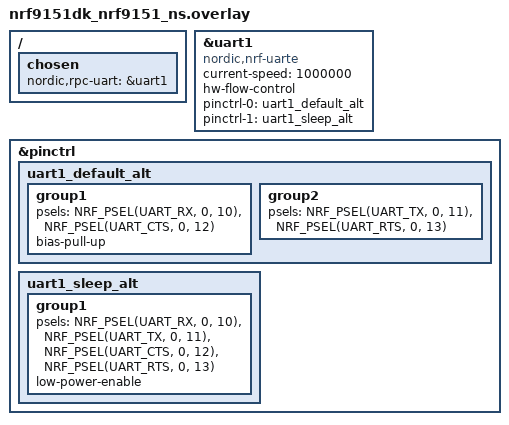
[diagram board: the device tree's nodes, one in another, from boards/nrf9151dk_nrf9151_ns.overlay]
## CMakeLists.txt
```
# Copyright (c) 2026 Nordic Semiconductor ASA
# SPDX-License-Identifier: LicenseRef-Nordic-5-Clause

cmake_minimum_required(VERSION 3.20.0)
find_package(Zephyr REQUIRED HINTS $ENV{ZEPHYR_BASE})
project(dect_rpc_server)

target_sources(app PRIVATE src/main.c)
```

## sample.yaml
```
# Copyright (c) 2026 Nordic Semiconductor ASA
# SPDX-License-Identifier: LicenseRef-Nordic-5-Clause

sample:
  name: DECT NR+ RPC server

common:
  tags:
    - ci_build
    - sysbuild
    - ci_samples_dect
  sysbuild: true
  build_only: true
  integration_platforms:
    - nrf9151dk/nrf9151/ns
  platform_allow:
    - nrf9151dk/nrf9151/ns

tests:
  sample.dect.dect_rpc_server: {}
  sample.dect.dect_rpc_server.rpc_uart_reliable:
    extra_args: EXTRA_CONF_FILE=rpc-uart-reliable.conf
```

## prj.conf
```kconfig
CONFIG_DECT=y

# Usually these RPC server is used when acting as PT
CONFIG_DECT_DEFAULT_DEV_TYPE_PT=y

# Modem library
CONFIG_NRF_MODEM_LIB=y
CONFIG_NRF_MODEM_LINK_BINARY_DECT=y
CONFIG_NRF_MODEM_LIB_ON_FAULT_APPLICATION_SPECIFIC=y
CONFIG_NRF_MODEM_LIB_SHMEM_RX_SIZE=6144
CONFIG_NRF_MODEM_LIB_SHMEM_TX_SIZE=12288
CONFIG_NRF_MODEM_LIB_CFUN_HOOKS=n
CONFIG_NRF_MODEM_LIB_TRACE=n

# DECT NR+ core and RPC sample
CONFIG_DECT_NR_RPC=y
CONFIG_DECT_NR_RPC_SERVER=y
CONFIG_DECT_NR_RPC_NET_IF=y
CONFIG_DECT_NR_RPC_SHELL=y

# DECT NR+ driver configuration
CONFIG_DECT_MDM=y
CONFIG_DECT_MDM_DRIVER_NRF=y

CONFIG_DECT_CLUSTER_MAX_CHILD_ASSOCIATION_COUNT=10
CONFIG_NET_IPV6_MAX_NEIGHBORS=10

CONFIG_DECT_MDM_NET_IF_NO_AUTO_START=n
CONFIG_NET_L2_DECT=y
CONFIG_NET_L2_DECT_MGMT=y

# Settings storage (DECT_MDM depends on SETTINGS; NVS backend needs FLASH + NVS)
CONFIG_FLASH=y
CONFIG_FLASH_MAP=y
CONFIG_MPU_ALLOW_FLASH_WRITE=y
CONFIG_NVS=y
CONFIG_SETTINGS=y
CONFIG_SETTINGS_NVS=y

# Modem configuration (align with dect_shell: MODEM_INFO for FW version in dect status)
CONFIG_MODEM_ANTENNA=n
CONFIG_MODEM_INFO=y
CONFIG_MODEM_INFO_ADD_NETWORK=n
CONFIG_MODEM_INFO_ADD_SIM=n

# nRF RPC over UART (server is initiator; init in main() after modem, no shell command)
CONFIG_NRF_RPC_UART_TRANSPORT=y
CONFIG_DECT_NR_RPC_UART_TRANSPORT=y
CONFIG_NRF_RPC_UART_RX_RINGBUF_SIZE=8192
CONFIG_NRF_RPC_GROUP_DEFAULT_INITIATOR=y
CONFIG_NRF_RPC_GROUP_INIT_WAIT_TIME=15000

# Default: non-reliable UART RPC (for throughput). Add rpc-uart-reliable.conf for reliable mode.
CONFIG_NRF_RPC_UART_RELIABLE=n
CONFIG_NRF_RPC_RESPONSE_TIMEOUT=50
CONFIG_NRF_RPC_CBOR=y
CONFIG_NRF_RPC_ZCBOR_BACKUPS=1
CONFIG_NRF_RPC_THREAD_STACK_SIZE=5632

CONFIG_NRF_RPC_THREAD_PRIORITY=0
CONFIG_NRF_RPC_THREAD_POOL_SIZE=5
CONFIG_NRF_RPC_CMD_CTX_POOL_SIZE=12

# DECT NR+ RPC server event pacing
CONFIG_DECT_NR_RPC_SERVER_EVT_PACING_MS=0

# UART
CONFIG_UART_LINE_CTRL=y
CONFIG_UART_INTERRUPT_DRIVEN=y

# Networking
CONFIG_NETWORKING=y
CONFIG_NET_NATIVE=y
CONFIG_NET_IPV6=y
CONFIG_NET_IPV4=n
CONFIG_NET_SOCKETS=y
CONFIG_NET_SOCKETS_OFFLOAD=n
CONFIG_NET_MGMT=y
CONFIG_NET_MGMT_EVENT=y
CONFIG_NET_MGMT_EVENT_INFO=y
CONFIG_NET_MGMT_EVENT_INFO_DEFAULT_DATA_SIZE=208
CONFIG_NET_MGMT_EVENT_STACK_SIZE=2048
CONFIG_NET_MGMT_EVENT_QUEUE_SIZE=20
CONFIG_NET_MGMT_EVENT_QUEUE_TIMEOUT=5000
CONFIG_NET_L2_DUMMY=n
CONFIG_NET_CONNECTION_MANAGER=y

CONFIG_NET_L2_DECT_CONN_MGR_AUTO_CONNECT=y
CONFIG_NET_L2_DECT_CONN_MGR_CONNECTION_PERSISTENCE=y

CONFIG_GETOPT_LONG=y
CONFIG_NET_IF_MAX_IPV6_COUNT=4
CONFIG_NET_INTERFACE_NAME=y
CONFIG_NET_STATISTICS=y

# ULA / DECT addressing; need room for e.g. link-local + ULA + global per iface.
CONFIG_NET_IF_UNICAST_IPV6_ADDR_COUNT=3

# RX stack: must be large enough when processing ping (IPv6 + ICMP + DECT L2 + RPC forward)
CONFIG_NET_RX_STACK_SIZE=4096
CONFIG_NET_TX_STACK_SIZE=2048

CONFIG_NET_BUF=y
CONFIG_NET_PKT_RX_COUNT=20
CONFIG_NET_BUF_RX_COUNT=40
CONFIG_NET_PKT_TX_COUNT=20
CONFIG_NET_BUF_TX_COUNT=40
CONFIG_NET_BUF_POOL_USAGE=y

# Heap and stacks
CONFIG_HEAP_MEM_POOL_SIZE=8192
CONFIG_MAIN_STACK_SIZE=4096
CONFIG_SYSTEM_WORKQUEUE_STACK_SIZE=3072

# TF-M configuration
CONFIG_TFM_PROFILE_TYPE_MINIMAL=y
CONFIG_TFM_SECURE_UART0=y
CONFIG_TFM_LOG_LEVEL_SILENCE=n
CONFIG_TFM_EXCEPTION_INFO_DUMP=y
# INFO reduces secure-side log traffic vs DEBUG during RPC/DECT throughput (still not silent).
CONFIG_TFM_SPM_LOG_LEVEL_INFO=y

# Device power management
CONFIG_PM_DEVICE=y
CONFIG_PM_DEVICE_SHELL=y
CONFIG_PM_DEVICE_RUNTIME=y
CONFIG_PM_DEVICE_RUNTIME_USE_DEDICATED_WQ=y

# Logging
CONFIG_LOG=y
CONFIG_NET_LOG=y
CONFIG_SHELL_LOG_BACKEND=y
CONFIG_LOG_BACKEND_UART=n
# INF level so DBG (receive_handler, cmd_ctx_alloc, hexdump, etc.) does not clutter ping output
CONFIG_NRF_RPC_TR_LOG_LEVEL_INF=y
CONFIG_NRF_RPC_LOG_LEVEL_INF=y

# DECT stack: INFO level logs for debugging modem/stack bring-up
CONFIG_DECT_MDM_LOG_LEVEL_INF=y
CONFIG_NET_L2_DECT_LOG_LEVEL_INF=y
CONFIG_NET_L2_DECT_MGMT_LOG_LEVEL_INF=y
CONFIG_NET_L2_DECT_BR_LOG_LEVEL_INF=y
CONFIG_NET_L2_DECT_CONN_MGR_LOG_LEVEL_INF=y

# Shell: local DECT L2 commands (dect status, dect scan, etc.) and net shell (net iface, etc.)
# Align with dect_shell to avoid stack overflow in shell_uart when running dect commands
CONFIG_SHELL=y
CONFIG_SHELL_PROMPT_UART="dect_rpc_server:~$ "
CONFIG_SHELL_BACKEND_SERIAL=y
CONFIG_SHELL_STACK_SIZE=9216
CONFIG_SHELL_CMD_BUFF_SIZE=4096
CONFIG_SHELL_ARGC_MAX=40
CONFIG_SHELL_BACKEND_SERIAL_RX_RING_BUFFER_SIZE=512
CONFIG_SHELL_BACKEND_SERIAL_API_INTERRUPT_DRIVEN=y
CONFIG_NET_SHELL=y

# Debugging options
CONFIG_ASSERT=y
CONFIG_ASSERT_VERBOSE=y

# Halt application, e.g. on assertion failure
CONFIG_RESET_ON_FATAL_ERROR=n
```

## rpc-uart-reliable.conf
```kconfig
# Extra Kconfig fragment: nRF RPC UART reliable mode (per-frame HDLC ACK + retries).
# Use on both client and server with the same fragment.
#
# Build from this sample directory (see README):
#   west build -p -b nrf9151dk/nrf9151/ns -- -DEXTRA_CONF_FILE=rpc-uart-reliable.conf
#
CONFIG_DECT_NR_RPC_SERVER_EVT_PACING_MS=20

CONFIG_NRF_RPC_UART_RELIABLE=y
CONFIG_NRF_RPC_UART_ACK_WAITING_TIME=2000
CONFIG_NRF_RPC_UART_TX_ATTEMPTS=5
```

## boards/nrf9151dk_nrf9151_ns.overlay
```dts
/*
 * Copyright (c) 2026 Nordic Semiconductor ASA
 *
 * SPDX-License-Identifier: LicenseRef-Nordic-5-Clause
 *
 * RPC over UART1 - RPC server side.
 *
 * Pins: RX P0.10, TX P0.11, CTS P0.12, RTS P0.13 (cross TX-RX and RTS-CTS to peer).
 */

/ {
	chosen {
		nordic,rpc-uart = &uart1;
	};
};

&uart1 {
	compatible = "nordic,nrf-uarte";
	status = "okay";
	current-speed = <1000000>;
	hw-flow-control;

	pinctrl-0 = <&uart1_default_alt>;
	pinctrl-1 = <&uart1_sleep_alt>;
	pinctrl-names = "default", "sleep";
};

&pinctrl {
	uart1_default_alt: uart1_default_alt {
		group1 {
			psels = <NRF_PSEL(UART_RX, 0, 10)>,
				<NRF_PSEL(UART_CTS, 0, 12)>;
			bias-pull-up;
		};

		group2 {
			psels = <NRF_PSEL(UART_TX, 0, 11)>,
				<NRF_PSEL(UART_RTS, 0, 13)>;
		};
	};

	uart1_sleep_alt: uart1_sleep_alt {
		group1 {
			psels = <NRF_PSEL(UART_RX, 0, 10)>,
				<NRF_PSEL(UART_TX, 0, 11)>,
				<NRF_PSEL(UART_CTS, 0, 12)>,
				<NRF_PSEL(UART_RTS, 0, 13)>;
			low-power-enable;
		};
	};
};
```

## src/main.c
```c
/*
 * Copyright (c) 2026 Nordic Semiconductor ASA
 *
 * SPDX-License-Identifier: LicenseRef-Nordic-5-Clause
 *
 * DECT NR+ RPC server: runs full DECT stack and modem; receives/sends
 * IPv6 from the RPC client over UART RPC.
 *
 * Init in main(): modem init, then nrf_rpc_init() so the server sends the group init.
 * Start the client first, then the server.
 */

#include <zephyr/kernel.h>
#include <zephyr/net/net_if.h>
#include <zephyr/net/net_core.h>
#include <zephyr/logging/log.h>

#include <nrf_modem.h>
#include <modem/nrf_modem_lib.h>
#include <nrf_rpc.h>

LOG_MODULE_REGISTER(main, LOG_LEVEL_INF);

static void rpc_err_handler(const struct nrf_rpc_err_report *report)
{
	LOG_ERR("RPC error: %d", report->code);
}

static const char *modem_fault_reason_str(uint32_t reason)
{
	switch (reason) {
	case NRF_MODEM_FAULT_UNDEFINED:
		return "Undefined fault";
	case NRF_MODEM_FAULT_HW_WD_RESET:
		return "HW WD reset";
	case NRF_MODEM_FAULT_HARDFAULT:
		return "Hard fault";
	case NRF_MODEM_FAULT_MEM_MANAGE:
		return "Memory management fault";
	case NRF_MODEM_FAULT_BUS:
		return "Bus fault";
	case NRF_MODEM_FAULT_USAGE:
		return "Usage fault";
	case NRF_MODEM_FAULT_SECURE_RESET:
		return "Secure control reset";
	case NRF_MODEM_FAULT_PANIC_DOUBLE:
		return "Error handler crash";
	case NRF_MODEM_FAULT_PANIC_RESET_LOOP:
		return "Reset loop";
	case NRF_MODEM_FAULT_ASSERT:
		return "Assert";
	case NRF_MODEM_FAULT_PANIC:
		return "Unconditional SW reset";
	case NRF_MODEM_FAULT_FLASH_ERASE:
		return "Flash erase fault";
	case NRF_MODEM_FAULT_FLASH_WRITE:
		return "Flash write fault";
	case NRF_MODEM_FAULT_POFWARN:
		return "Undervoltage fault";
	case NRF_MODEM_FAULT_THWARN:
		return "Overtemperature fault";
	default:
		return "Unknown reason";
	}
}

void nrf_modem_fault_handler(struct nrf_modem_fault_info *fault_info)
{
	LOG_ERR("Modem fault: reason=0x%x (%s), PC=0x%x",
		fault_info->reason,
		modem_fault_reason_str(fault_info->reason),
		fault_info->program_counter);

	__ASSERT(false, "Modem crash detected, halting application");
}

int main(void)
{
	int err;

	LOG_INF("DECT RPC server running. DECT interface receives/sends via RPC.");

	/* Initialize modem library; this runs NRF_MODEM_LIB_ON_INIT callbacks (DECT stack init). */
	err = nrf_modem_lib_init();
	if (err) {
		LOG_ERR("nrf_modem_lib_init failed: %d", err);
		return err;
	}
	LOG_INF("nRF Modem library initialized");

	/* Initialize RPC (server is initiator: sends group init to client). */
	LOG_INF("Initializing RPC...");
	err = nrf_rpc_init(rpc_err_handler);
	if (err != 0) {
		LOG_ERR("nrf_rpc_init failed: %d", err);
		return err;
	}
	LOG_INF("RPC initialized");

	return 0;
}
```
